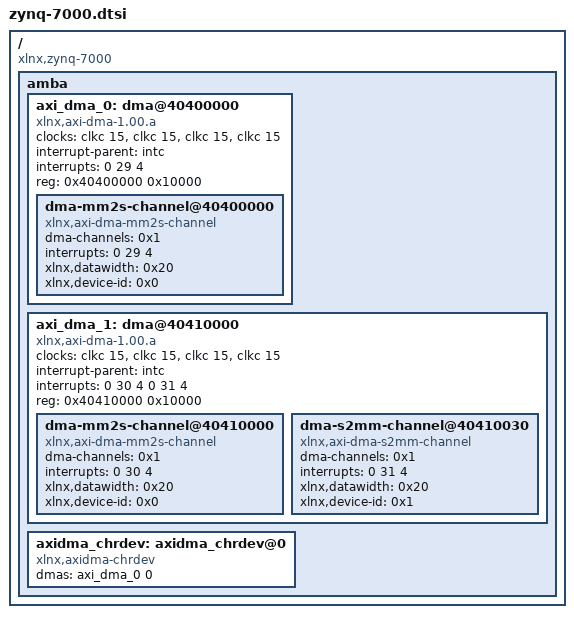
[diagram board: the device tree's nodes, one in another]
/*
 *  Copyright (C) 2011 - 2014 Xilinx
 *
 * This software is licensed under the terms of the GNU General Public
 * License version 2, as published by the Free Software Foundation, and
 * may be copied, distributed, and modified under those terms.
 *
 * This program is distributed in the hope that it will be useful,
 * but WITHOUT ANY WARRANTY; without even the implied warranty of
 * MERCHANTABILITY or FITNESS FOR A PARTICULAR PURPOSE.  See the
 * GNU General Public License for more details.
 */
/include/ "skeleton.dtsi"

/ {
	compatible = "xlnx,zynq-7000";

	amba: amba {
		axi_dma_0: dma@40400000 {
			#dma-cells = <1>;
		    clock-names = "s_axi_lite_aclk", "m_axi_sg_aclk", "m_axi_mm2s_aclk", "m_axi_s2mm_aclk";
		    clocks = <&clkc 15>, <&clkc 15>, <&clkc 15>, <&clkc 15>;
			compatible = "xlnx,axi-dma-1.00.a";
			interrupt-parent = <&intc>;
			interrupts = <0 29 4 >;
			reg = <0x40400000 0x10000>;
			dma-mm2s-channel@40400000 {
				compatible = "xlnx,axi-dma-mm2s-channel";
				dma-channels = <0x1>;
				interrupts = <0 29 4>;
				xlnx,datawidth = <0x20>;
				xlnx,device-id = <0x0>;
			};
		};
		axi_dma_1: dma@40410000 {
		    #dma-cells = <1>;
		    clock-names = "s_axi_lite_aclk", "m_axi_sg_aclk", "m_axi_mm2s_aclk", "m_axi_s2mm_aclk";
		    clocks = <&clkc 15>, <&clkc 15>, <&clkc 15>, <&clkc 15>;
			compatible = "xlnx,axi-dma-1.00.a";
			interrupt-parent = <&intc>;
			interrupts = <0 30 4 0 31 4>;
			reg = <0x40410000 0x10000>;
			dma-mm2s-channel@40410000 {
				compatible = "xlnx,axi-dma-mm2s-channel";
				dma-channels = <0x1>;
				interrupts = <0 30 4>;
				xlnx,datawidth = <0x20>;
				xlnx,device-id = <0x0>;
			};
			
			dma-s2mm-channel@40410030 {
				compatible = "xlnx,axi-dma-s2mm-channel";
				dma-channels = <0x1>;
				interrupts = <0 31 4>;
				xlnx,datawidth = <0x20>;
				xlnx,device-id = <0x1>;
			};
			
	    };

	    axidma_chrdev: axidma_chrdev@0 {
            compatible = "xlnx,axidma-chrdev";
            dmas = <&axi_dma_0 0>;
            dma-names = "tx_channel";
        };

/*
	    axidma_chrdev: axidma_chrdev@0 {
            compatible = "xlnx,axidma-chrdev";
            dmas = <&axi_dma_1 0 &axi_dma_1 1>;
            dma-names = "tx_channel", "rx_channel";
        };
*/

	};
};
